AUTOSAR XML (schema 4-0-3)
package /ComponentTypes
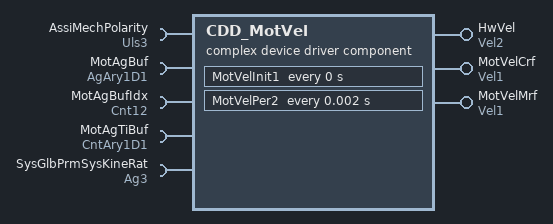
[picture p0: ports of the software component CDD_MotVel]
  complex device driver sw component type CDD_MotVel
    provide port HwVel: nonqueued-sender-com-spec{data-element=Val, init-value=0}, provided-interface=Vel2
    provide port MotVelCrf: nonqueued-sender-com-spec{data-element=Val, init-value=0}, provided-interface=Vel1
    provide port MotVelMrf: nonqueued-sender-com-spec{data-element=Val, init-value=0}, provided-interface=Vel1
    5 x require port:
      AssiMechPolarity: nonqueued-receiver-com-spec{data-element=Val, filter=data-filter-type=ALWAYS, init-value=1}, required-interface=Uls3
      MotAgBuf: nonqueued-receiver-com-spec{data-element=Ary1D, filter=data-filter-type=ALWAYS, init-value=8 x 0}, required-interface=AgAry1D1
      MotAgBufIdx: nonqueued-receiver-com-spec{data-element=Val, filter=data-filter-type=ALWAYS, init-value=0}, required-interface=Cnt12
      MotAgTiBuf: nonqueued-receiver-com-spec{data-element=Ary1D, filter=data-filter-type=ALWAYS, init-value=[0, 62, 125, 187, 250, 312, 375, 437]}, required-interface=CntAry1D1
      SysGlbPrmSysKineRat: parameter-require-com-spec{init-value=22, parameter=Val}, required-interface=Ag3
    behavior CDD_MotVel_InternalBehavior: data-type-mapping=Nexteer
      ar-typed-per-instance-memorys:
        8 x data, all with sw-calibration-access=READ-ONLY:
          dMotVelAvrgTi: type=Ti7
          dMotVelMotAgRef: type=u0p16
          dMotVelTiStampRef: type=Ti7
          MotAgBufIdx: type=Cnt22
          MotAgBufIdxPrev: type=uint8
          MotAgBufPrev: type=AgAry1D2
          MotAgTiBufPrev: type=CntAry1D2
          MotVelIninCntr: type=Cnt18
      timing event CDD_MotVel_InitEvent: start-on-event=MotVelInit1, period=0
      timing event TMT_MotVelPer2: start-on-event=MotVelPer2, period=0.002
      runnable MotVelInit1
      runnable MotVelPer2
        data-receive-point-by-arguments:
          4 x access:
            REC_AssiMechPolarity_Val: accessed-variable=AssiMechPolarity.Val
            REC_MotAgBuf_Ary1D: accessed-variable=MotAgBuf.Ary1D
            REC_MotAgBufIdx_Val: accessed-variable=MotAgBufIdx.Val
            REC_MotAgTiBuf_Ary1D: accessed-variable=MotAgTiBuf.Ary1D
        data-send-points:
          access SEND_HwVel_Val: accessed-variable=HwVel.Val
          access SEND_MotVelCrf_Val: accessed-variable=MotVelCrf.Val
          access SEND_MotVelMrf_Val: accessed-variable=MotVelMrf.Val
  swc implementation CDD_MotVel_Implementation: behavior=CDD_MotVel_InternalBehavior
    code-descriptors:
      code Default: artifact-descriptors=autosar-engineering-object={short-label=Default, category=SWSRC}
